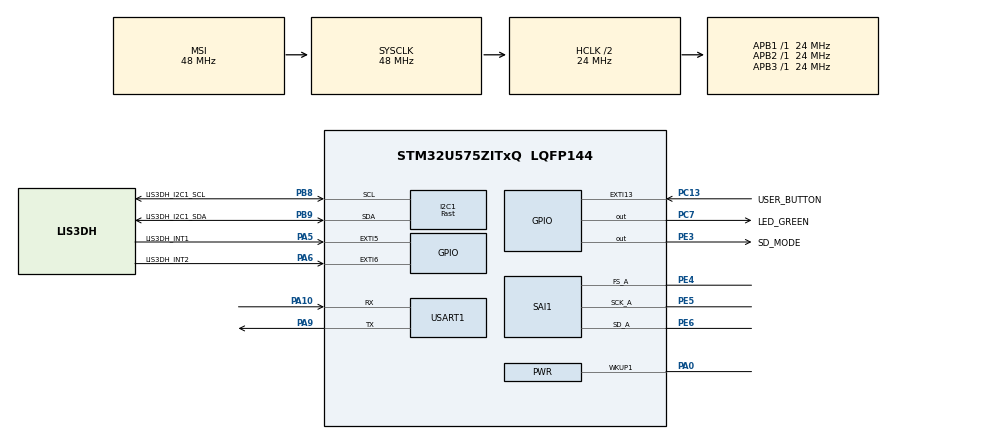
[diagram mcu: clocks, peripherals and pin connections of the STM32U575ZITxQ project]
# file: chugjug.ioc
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CORTEX_M33_NS.userName=CORTEX_M33
GPDMA1.PRIORITY_LL_GPDMACH0=DMA_HIGH_PRIORITY
I2C1.I2C_Speed_Mode=I2C_Fast
I2C1.Timing=0x00200C28
Mcu.Family=STM32U5
Mcu.Name=STM32U575ZITxQ
Mcu.Package=LQFP144
NVIC.EXTI13_IRQn=true\:0\:0\:false\:false\:true\:true\:true\:true
NVIC.EXTI5_IRQn=true\:0\:0\:false\:false\:true\:true\:true\:true
NVIC.EXTI6_IRQn=true\:0\:0\:false\:false\:true\:true\:true\:true
NVIC.GPDMA1_Channel0_IRQn=true\:0\:0\:false\:false\:true\:true\:true\:true
NVIC.PriorityGroup=NVIC_PRIORITYGROUP_3
NVIC.SAI1_IRQn=true\:0\:0\:false\:false\:true\:true\:true\:true
NVIC.TIM17_IRQn=true\:7\:0\:false\:false\:true\:false\:true\:true
NVIC.TIM1_UP_IRQn=true\:1\:0\:true\:false\:true\:true\:true\:true
NVIC.TimeBase=TIM17_IRQn
NVIC.TimeBaseIP=TIM17
PA0.Mode=WakeUp1
PA0.Signal=PWR_WKUP1
PA10.Mode=Asynchronous
PA10.Signal=USART1_RX
PA13\ (JTMS/SWDIO).Signal=DEBUG_JTMS-SWDIO
PA14\ (JTCK/SWCLK).Signal=DEBUG_JTCK-SWCLK
PA5.GPIO_Label=LIS3DH_INT1
PA5.GPIO_PuPd=GPIO_PULLDOWN
PA5.Signal=GPXTI5
PA6.GPIO_Label=LIS3DH_INT2
PA6.GPIO_PuPd=GPIO_PULLDOWN
PA6.Signal=GPXTI6
PA9.Mode=Asynchronous
PA9.Signal=USART1_TX
PB3\ (JTDO/TRACESWO).Signal=DEBUG_JTDO-SWO
PB8.GPIO_Label=LIS3DH_I2C1_SCL
PB8.Mode=I2C
PB8.Signal=I2C1_SCL
PB9.GPIO_Label=LIS3DH_I2C1_SDA
PB9.Mode=I2C
PB9.Signal=I2C1_SDA
PC13.GPIO_Label=USER_BUTTON
PC13.GPIO_ModeDefaultEXTI=GPIO_MODE_IT_RISING
PC13.GPIO_PuPd=GPIO_PULLDOWN
PC13.Signal=GPXTI13
PC14-OSC32_IN\ (PC14).Signal=RCC_OSC32_IN
PC15-OSC32_OUT\ (PC15).Signal=RCC_OSC32_OUT
PC7.GPIO_Label=LED_GREEN
PC7.Signal=GPIO_Output
PE3.GPIO_Label=SD_MODE
PE3.GPIO_PuPd=GPIO_NOPULL
PE3.Signal=GPIO_Output
PE4.GPIO_Speed=GPIO_SPEED_FREQ_VERY_HIGH
PE4.Mode=SAI_A_Master
PE4.Signal=SAI1_FS_A
PE5.GPIO_Speed=GPIO_SPEED_FREQ_VERY_HIGH
PE5.Mode=SAI_A_Master
PE5.Signal=SAI1_SCK_A
PE6.GPIO_Speed=GPIO_SPEED_FREQ_VERY_HIGH
PE6.Mode=SAI_A_Master
PE6.Signal=SAI1_SD_A
PWR.PowerMode=PWR_SMPS_SUPPLY
ProjectManager.HeapSize=0x200
ProjectManager.StackSize=0x400
ProjectManager.TargetToolchain=CMake
RCC.ADCFreq_Value=16000000
RCC.AHBCLKDivider=RCC_SYSCLK_DIV2
RCC.AHBFreq_Value=24000000
RCC.APB1Freq_Value=24000000
RCC.APB1TimFreq_Value=24000000
RCC.APB2Freq_Value=24000000
RCC.APB2TimFreq_Value=24000000
RCC.APB3Freq_Value=24000000
RCC.CortexFreq_Value=24000000
RCC.DACCLockSelectionVirtual=RCC_DAC1CLKSOURCE_LSI
RCC.EPOD_VALUE=48000000
RCC.HCLKFreq_Value=24000000
RCC.HSE_VALUE=16000000
RCC.HSI48_VALUE=48000000
RCC.HSI_VALUE=16000000
RCC.LSE_VALUE=32768
RCC.LSIDIV_VALUE=32000
RCC.MSIClockRange=RCC_MSIRANGE_0
RCC.MSI_VALUE=48000000
RCC.PLL2FRACN=2048
RCC.PLL2M=3
RCC.PLL2N=11
RCC.SYSCLKFreq_VALUE=48000000
RCC.USBFreq_Value=48000000
RCC.VCOOutputFreq_Value=6192000000
SAI1.AudioFrequency-SAI_A_Master=SAI_AUDIO_FREQUENCY_44K
SAI1.ErrorAudioFreq-SAI_A_Master=-0.35 %
SAI1.InitProtocol-SAI_A_Master=Enable
SAI1.Instance-SAI_A_Master=SAI$Index_Block_A
SAI1.MckOutput-SAI_A_Master=SAI_MCK_OUTPUT_DISABLE
SAI1.MonoStereoMode-SAI_A_Master=SAI_MONOMODE
SAI1.RealAudioFreq-SAI_A_Master=43.945 KHz
SAI1.VirtualMode-SAI_A_Master=VM_MASTER
SAI1.VirtualProtocol-SAI_A_BASIC=VM_BASIC_PROTOCOL
TIM1.AutoReloadPreload=TIM_AUTORELOAD_PRELOAD_ENABLE
TIM1.PeriodNoDither=19
TIM1.Prescaler=23999
USART1.VirtualMode-Asynchronous=VM_ASYNC
VP_GPDMA1_VS_GPDMACH0.Mode=LINKEDLIST_GPDMACH0
VP_ICACHE_VS_ENABLE_ICACHE_MEMORY.Mode=Memoryregions
VP_ICACHE_VS_ICACHE.Mode=DirectMappedCache
VP_LPBAMQUEUE_VS_QUEUE.Mode=QUEUEMODE
VP_LPBAM_VS_SIG1.Mode=SmartRun
VP_LPBAM_VS_SIG4.Mode=LPDMA1
VP_MEMORYMAP_VS_MEMORYMAP.Mode=CurAppReg
VP_PWR_VS_DBSignals.Mode=DisableDeadBatterySignals
VP_PWR_VS_LPOM.Mode=PowerOptimisation
VP_PWR_VS_SECSignals.Mode=Security/Privilege
VP_SAI1_VP_$IpInstance_SAIA_SAI_BASIC.Mode=SAI_A_BASIC
VP_SYS_VS_tim17.Mode=TIM17
VP_TIM1_VS_ClockSourceINT.Mode=Internal
board=NUCLEO-U575ZI-Q

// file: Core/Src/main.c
/* USER CODE BEGIN Header */
/**
  ******************************************************************************
  * @file           : main.c
  * @brief          : Main program body
  ******************************************************************************
  * @attention
  *
  * Copyright (c) 2026 STMicroelectronics.
  * All rights reserved.
  *
  * This software is licensed under terms that can be found in the LICENSE file
  * in the root directory of this software component.
  * If no LICENSE file comes with this software, it is provided AS-IS.
  *
  ******************************************************************************
  */
/* USER CODE END Header */
#include "main.h"

DMA_HandleTypeDef handle_GPDMA1_Channel0;

I2C_HandleTypeDef hi2c1;

SAI_HandleTypeDef hsai_BlockA1;

TIM_HandleTypeDef htim1;

UART_HandleTypeDef huart1;

void SystemClock_Config(void);
static void SystemPower_Config(void);
static void MX_GPIO_Init(void);
static void MX_GPDMA1_Init(void);
static void MX_ICACHE_Init(void);
static void MX_I2C1_Init(void);
static void MX_SAI1_Init(void);
static void MX_USART1_UART_Init(void);
static void MX_TIM1_Init(void);
/* USER CODE BEGIN PFP */
#define PUTCHAR_PROTOTYPE int __io_putchar(int ch)
/* USER CODE END PFP */

int main(void)
{

  /* MCU Configuration--------------------------------------------------------*/

  /* Reset of all peripherals, Initializes the Flash interface and the Systick. */
  HAL_Init();

  /* Configure the System Power */
  SystemPower_Config();

  /* Configure the system clock */
  SystemClock_Config();

  /* Initialize all configured peripherals */
  MX_GPIO_Init();
  MX_GPDMA1_Init();
  MX_ICACHE_Init();
  MX_I2C1_Init();
  MX_SAI1_Init();
  MX_USART1_UART_Init();
  MX_TIM1_Init();
  /* USER CODE BEGIN 2 */
  chugjug_init();

  /* USER CODE END 2 */

  /* Infinite loop */
  /* USER CODE BEGIN WHILE */
  chugjug_loop();
  while (1)
  {
    /* USER CODE END WHILE */

  }
}

void SystemClock_Config(void)
{
  RCC_OscInitTypeDef RCC_OscInitStruct = {0};
  RCC_ClkInitTypeDef RCC_ClkInitStruct = {0};

  /** Configure the main internal regulator output voltage
  */
  if (HAL_PWREx_ControlVoltageScaling(PWR_REGULATOR_VOLTAGE_SCALE3) != HAL_OK)
  {
    Error_Handler();
  }

  /** Initializes the CPU, AHB and APB buses clocks
  */
  RCC_OscInitStruct.OscillatorType = RCC_OSCILLATORTYPE_MSI;
  RCC_OscInitStruct.MSIState = RCC_MSI_ON;
  RCC_OscInitStruct.MSICalibrationValue = RCC_MSICALIBRATION_DEFAULT;
  RCC_OscInitStruct.MSIClockRange = RCC_MSIRANGE_0;
  RCC_OscInitStruct.PLL.PLLState = RCC_PLL_NONE;
  if (HAL_RCC_OscConfig(&RCC_OscInitStruct) != HAL_OK)
  {
    Error_Handler();
  }

  /** Initializes the CPU, AHB and APB buses clocks
  */
  RCC_ClkInitStruct.ClockType = RCC_CLOCKTYPE_HCLK|RCC_CLOCKTYPE_SYSCLK
                              |RCC_CLOCKTYPE_PCLK1|RCC_CLOCKTYPE_PCLK2
                              |RCC_CLOCKTYPE_PCLK3;
  RCC_ClkInitStruct.SYSCLKSource = RCC_SYSCLKSOURCE_MSI;
  RCC_ClkInitStruct.AHBCLKDivider = RCC_SYSCLK_DIV2;
  RCC_ClkInitStruct.APB1CLKDivider = RCC_HCLK_DIV1;
  RCC_ClkInitStruct.APB2CLKDivider = RCC_HCLK_DIV1;
  RCC_ClkInitStruct.APB3CLKDivider = RCC_HCLK_DIV1;

  if (HAL_RCC_ClockConfig(&RCC_ClkInitStruct, FLASH_LATENCY_0) != HAL_OK)
  {
    Error_Handler();
  }
}

/**
  * @brief Power Configuration
  * @retval None
  */
static void SystemPower_Config(void)
{

  /*
   * Disable the internal Pull-Up in Dead Battery pins of UCPD peripheral
   */
  HAL_PWREx_DisableUCPDDeadBattery();

  /*
   * Switch to SMPS regulator instead of LDO
   */
  if (HAL_PWREx_ConfigSupply(PWR_SMPS_SUPPLY) != HAL_OK)
  {
    Error_Handler();
  }
}

static void MX_GPDMA1_Init(void)
{

  /* Peripheral clock enable */
  __HAL_RCC_GPDMA1_CLK_ENABLE();

  /* GPDMA1 interrupt Init */
    HAL_NVIC_SetPriority(GPDMA1_Channel0_IRQn, 0, 0);
    HAL_NVIC_EnableIRQ(GPDMA1_Channel0_IRQn);

  handle_GPDMA1_Channel0.Instance = GPDMA1_Channel0;
  handle_GPDMA1_Channel0.InitLinkedList.Priority = DMA_HIGH_PRIORITY;
  handle_GPDMA1_Channel0.InitLinkedList.LinkStepMode = DMA_LSM_FULL_EXECUTION;
  handle_GPDMA1_Channel0.InitLinkedList.LinkAllocatedPort = DMA_LINK_ALLOCATED_PORT0;
  handle_GPDMA1_Channel0.InitLinkedList.TransferEventMode = DMA_TCEM_LAST_LL_ITEM_TRANSFER;
  handle_GPDMA1_Channel0.InitLinkedList.LinkedListMode = DMA_LINKEDLIST_NORMAL;
  if (HAL_DMAEx_List_Init(&handle_GPDMA1_Channel0) != HAL_OK)
  {
    Error_Handler();
  }
  if (HAL_DMA_ConfigChannelAttributes(&handle_GPDMA1_Channel0, DMA_CHANNEL_NPRIV) != HAL_OK)
  {
    Error_Handler();
  }

}

static void MX_I2C1_Init(void)
{

  hi2c1.Instance = I2C1;
  hi2c1.Init.Timing = 0x00200C28;
  hi2c1.Init.OwnAddress1 = 0;
  hi2c1.Init.AddressingMode = I2C_ADDRESSINGMODE_7BIT;
  hi2c1.Init.DualAddressMode = I2C_DUALADDRESS_DISABLE;
  hi2c1.Init.OwnAddress2 = 0;
  hi2c1.Init.OwnAddress2Masks = I2C_OA2_NOMASK;
  hi2c1.Init.GeneralCallMode = I2C_GENERALCALL_DISABLE;
  hi2c1.Init.NoStretchMode = I2C_NOSTRETCH_DISABLE;
  if (HAL_I2C_Init(&hi2c1) != HAL_OK)
  {
    Error_Handler();
  }

  /** Configure Analogue filter
  */
  if (HAL_I2CEx_ConfigAnalogFilter(&hi2c1, I2C_ANALOGFILTER_ENABLE) != HAL_OK)
  {
    Error_Handler();
  }

  /** Configure Digital filter
  */
  if (HAL_I2CEx_ConfigDigitalFilter(&hi2c1, 0) != HAL_OK)
  {
    Error_Handler();
  }

}

static void MX_ICACHE_Init(void)
{

  /** Enable instruction cache in 1-way (direct mapped cache)
  */
  if (HAL_ICACHE_ConfigAssociativityMode(ICACHE_1WAY) != HAL_OK)
  {
    Error_Handler();
  }
  if (HAL_ICACHE_Enable() != HAL_OK)
  {
    Error_Handler();
  }

}

static void MX_SAI1_Init(void)
{

  hsai_BlockA1.Instance = SAI1_Block_A;
  hsai_BlockA1.Init.AudioMode = SAI_MODEMASTER_TX;
  hsai_BlockA1.Init.Synchro = SAI_ASYNCHRONOUS;
  hsai_BlockA1.Init.OutputDrive = SAI_OUTPUTDRIVE_DISABLE;
  hsai_BlockA1.Init.NoDivider = SAI_MASTERDIVIDER_ENABLE;
  hsai_BlockA1.Init.FIFOThreshold = SAI_FIFOTHRESHOLD_EMPTY;
  hsai_BlockA1.Init.AudioFrequency = SAI_AUDIO_FREQUENCY_44K;
  hsai_BlockA1.Init.SynchroExt = SAI_SYNCEXT_DISABLE;
  hsai_BlockA1.Init.MckOutput = SAI_MCK_OUTPUT_DISABLE;
  hsai_BlockA1.Init.MonoStereoMode = SAI_MONOMODE;
  hsai_BlockA1.Init.CompandingMode = SAI_NOCOMPANDING;
  hsai_BlockA1.Init.TriState = SAI_OUTPUT_NOTRELEASED;
  if (HAL_SAI_InitProtocol(&hsai_BlockA1, SAI_I2S_STANDARD, SAI_PROTOCOL_DATASIZE_16BIT, 2) != HAL_OK)
  {
    Error_Handler();
  }

}

static void MX_TIM1_Init(void)
{

  TIM_ClockConfigTypeDef sClockSourceConfig = {0};
  TIM_MasterConfigTypeDef sMasterConfig = {0};

  htim1.Instance = TIM1;
  htim1.Init.Prescaler = 23999;
  htim1.Init.CounterMode = TIM_COUNTERMODE_UP;
  htim1.Init.Period = 19;
  htim1.Init.ClockDivision = TIM_CLOCKDIVISION_DIV1;
  htim1.Init.RepetitionCounter = 0;
  htim1.Init.AutoReloadPreload = TIM_AUTORELOAD_PRELOAD_ENABLE;
  if (HAL_TIM_Base_Init(&htim1) != HAL_OK)
  {
    Error_Handler();
  }
  sClockSourceConfig.ClockSource = TIM_CLOCKSOURCE_INTERNAL;
  if (HAL_TIM_ConfigClockSource(&htim1, &sClockSourceConfig) != HAL_OK)
  {
    Error_Handler();
  }
  sMasterConfig.MasterOutputTrigger = TIM_TRGO_RESET;
  sMasterConfig.MasterOutputTrigger2 = TIM_TRGO2_RESET;
  sMasterConfig.MasterSlaveMode = TIM_MASTERSLAVEMODE_DISABLE;
  if (HAL_TIMEx_MasterConfigSynchronization(&htim1, &sMasterConfig) != HAL_OK)
  {
    Error_Handler();
  }

}

static void MX_USART1_UART_Init(void)
{

  huart1.Instance = USART1;
  huart1.Init.BaudRate = 115200;
  huart1.Init.WordLength = UART_WORDLENGTH_8B;
  huart1.Init.StopBits = UART_STOPBITS_1;
  huart1.Init.Parity = UART_PARITY_NONE;
  huart1.Init.Mode = UART_MODE_TX_RX;
  huart1.Init.HwFlowCtl = UART_HWCONTROL_NONE;
  huart1.Init.OverSampling = UART_OVERSAMPLING_16;
  huart1.Init.OneBitSampling = UART_ONE_BIT_SAMPLE_DISABLE;
  huart1.Init.ClockPrescaler = UART_PRESCALER_DIV1;
  huart1.AdvancedInit.AdvFeatureInit = UART_ADVFEATURE_NO_INIT;
  if (HAL_UART_Init(&huart1) != HAL_OK)
  {
    Error_Handler();
  }
  if (HAL_UARTEx_SetTxFifoThreshold(&huart1, UART_TXFIFO_THRESHOLD_1_8) != HAL_OK)
  {
    Error_Handler();
  }
  if (HAL_UARTEx_SetRxFifoThreshold(&huart1, UART_RXFIFO_THRESHOLD_1_8) != HAL_OK)
  {
    Error_Handler();
  }
  if (HAL_UARTEx_DisableFifoMode(&huart1) != HAL_OK)
  {
    Error_Handler();
  }

}

static void MX_GPIO_Init(void)
{
  GPIO_InitTypeDef GPIO_InitStruct = {0};

  /* GPIO Ports Clock Enable */
  __HAL_RCC_GPIOE_CLK_ENABLE();
  __HAL_RCC_GPIOC_CLK_ENABLE();
  __HAL_RCC_GPIOA_CLK_ENABLE();
  __HAL_RCC_GPIOB_CLK_ENABLE();

  /*Configure GPIO pin Output Level */
  HAL_GPIO_WritePin(SD_MODE_GPIO_Port, SD_MODE_Pin, GPIO_PIN_RESET);

  /*Configure GPIO pin Output Level */
  HAL_GPIO_WritePin(LED_GREEN_GPIO_Port, LED_GREEN_Pin, GPIO_PIN_RESET);

  /*Configure GPIO pin : SD_MODE_Pin */
  GPIO_InitStruct.Pin = SD_MODE_Pin;
  GPIO_InitStruct.Mode = GPIO_MODE_OUTPUT_PP;
  GPIO_InitStruct.Pull = GPIO_NOPULL;
  GPIO_InitStruct.Speed = GPIO_SPEED_FREQ_LOW;
  HAL_GPIO_Init(SD_MODE_GPIO_Port, &GPIO_InitStruct);

  /*Configure GPIO pin : USER_BUTTON_Pin */
  GPIO_InitStruct.Pin = USER_BUTTON_Pin;
  GPIO_InitStruct.Mode = GPIO_MODE_IT_RISING;
  GPIO_InitStruct.Pull = GPIO_PULLDOWN;
  HAL_GPIO_Init(USER_BUTTON_GPIO_Port, &GPIO_InitStruct);

  /*Configure GPIO pins : LIS3DH_INT1_Pin LIS3DH_INT2_Pin */
  GPIO_InitStruct.Pin = LIS3DH_INT1_Pin|LIS3DH_INT2_Pin;
  GPIO_InitStruct.Mode = GPIO_MODE_IT_RISING;
  GPIO_InitStruct.Pull = GPIO_PULLDOWN;
  HAL_GPIO_Init(GPIOA, &GPIO_InitStruct);

  /*Configure GPIO pin : LED_GREEN_Pin */
  GPIO_InitStruct.Pin = LED_GREEN_Pin;
  GPIO_InitStruct.Mode = GPIO_MODE_OUTPUT_PP;
  GPIO_InitStruct.Pull = GPIO_NOPULL;
  GPIO_InitStruct.Speed = GPIO_SPEED_FREQ_LOW;
  HAL_GPIO_Init(LED_GREEN_GPIO_Port, &GPIO_InitStruct);

  /* EXTI interrupt init*/
  HAL_NVIC_SetPriority(EXTI5_IRQn, 0, 0);
  HAL_NVIC_EnableIRQ(EXTI5_IRQn);

  HAL_NVIC_SetPriority(EXTI6_IRQn, 0, 0);
  HAL_NVIC_EnableIRQ(EXTI6_IRQn);

  HAL_NVIC_SetPriority(EXTI13_IRQn, 0, 0);
  HAL_NVIC_EnableIRQ(EXTI13_IRQn);

}

/* USER CODE BEGIN 4 */
/**
  * @brief  Retargets the C library printf function to the USART.
  *   None
  * @retval None
  */
PUTCHAR_PROTOTYPE
{
  /* Place your implementation of fputc here */
  /* e.g. write a character to the USART1 and Loop until the end of transmission */
  HAL_UART_Transmit(&huart1, (uint8_t *)&ch, 1, 0xFFFF);

  return ch;
}

void HAL_GPIO_EXTI_Rising_Callback(uint16_t GPIO_Pin) {
    chugjug_gpio_exti_callback(GPIO_Pin);
}

/* USER CODE END 4 */

void HAL_TIM_PeriodElapsedCallback(TIM_HandleTypeDef *htim)
{
  if (htim->Instance == TIM17)
  {
    HAL_IncTick();
  }
  /* USER CODE BEGIN Callback 1 */
  chugjug_timer_period_elapsed_callback(htim);

  /* USER CODE END Callback 1 */
}

void Error_Handler(void)
{
  __disable_irq();
  while (1)
  {
  }
}
